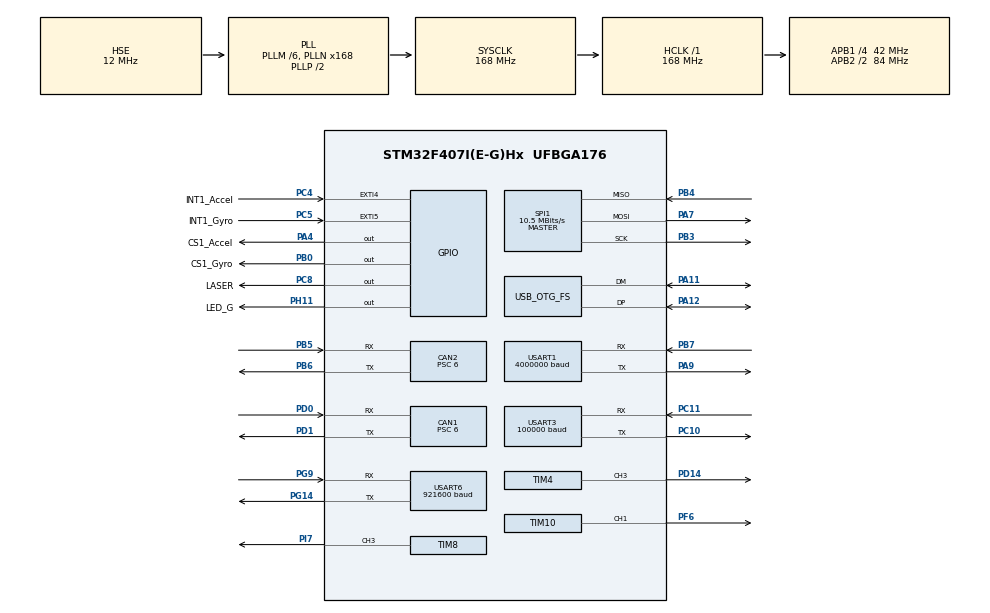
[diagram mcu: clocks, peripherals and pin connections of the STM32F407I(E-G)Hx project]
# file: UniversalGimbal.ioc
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CAN1.BS1=CAN_BS1_3TQ
CAN1.BS2=CAN_BS2_3TQ
CAN1.CalculateBaudRate=1000000
CAN1.CalculateTimeBit=1000
CAN1.CalculateTimeQuantum=142.85714285714286
CAN1.NART=ENABLE
CAN1.Prescaler=6
CAN2.BS1=CAN_BS1_3TQ
CAN2.BS2=CAN_BS2_3TQ
CAN2.CalculateBaudRate=1000000
CAN2.CalculateTimeBit=1000
CAN2.CalculateTimeQuantum=142.85714285714286
CAN2.Prescaler=6
Dma.Request0=SPI1_RX
Dma.Request1=SPI1_TX
Dma.Request2=USART6_RX
Dma.Request3=USART6_TX
Dma.Request4=USART3_RX
Dma.Request5=USART1_RX
Dma.Request6=USART1_TX
Dma.SPI1_RX.0.Direction=DMA_PERIPH_TO_MEMORY
Dma.SPI1_RX.0.FIFOMode=DMA_FIFOMODE_DISABLE
Dma.SPI1_RX.0.Instance=DMA2_Stream0
Dma.SPI1_RX.0.MemDataAlignment=DMA_MDATAALIGN_BYTE
Dma.SPI1_RX.0.MemInc=DMA_MINC_ENABLE
Dma.SPI1_RX.0.Mode=DMA_NORMAL
Dma.SPI1_RX.0.PeriphDataAlignment=DMA_PDATAALIGN_BYTE
Dma.SPI1_RX.0.PeriphInc=DMA_PINC_DISABLE
Dma.SPI1_RX.0.Priority=DMA_PRIORITY_HIGH
Dma.SPI1_TX.1.Direction=DMA_MEMORY_TO_PERIPH
Dma.SPI1_TX.1.FIFOMode=DMA_FIFOMODE_DISABLE
Dma.SPI1_TX.1.Instance=DMA2_Stream3
Dma.SPI1_TX.1.MemDataAlignment=DMA_MDATAALIGN_BYTE
Dma.SPI1_TX.1.MemInc=DMA_MINC_ENABLE
Dma.SPI1_TX.1.Mode=DMA_NORMAL
Dma.SPI1_TX.1.PeriphDataAlignment=DMA_PDATAALIGN_BYTE
Dma.SPI1_TX.1.PeriphInc=DMA_PINC_DISABLE
Dma.SPI1_TX.1.Priority=DMA_PRIORITY_HIGH
Dma.USART1_RX.5.Direction=DMA_PERIPH_TO_MEMORY
Dma.USART1_RX.5.FIFOMode=DMA_FIFOMODE_DISABLE
Dma.USART1_RX.5.Instance=DMA2_Stream2
Dma.USART1_RX.5.MemDataAlignment=DMA_MDATAALIGN_BYTE
Dma.USART1_RX.5.MemInc=DMA_MINC_ENABLE
Dma.USART1_RX.5.Mode=DMA_NORMAL
Dma.USART1_RX.5.PeriphDataAlignment=DMA_PDATAALIGN_BYTE
Dma.USART1_RX.5.PeriphInc=DMA_PINC_DISABLE
Dma.USART1_RX.5.Priority=DMA_PRIORITY_HIGH
Dma.USART1_TX.6.Direction=DMA_MEMORY_TO_PERIPH
Dma.USART1_TX.6.FIFOMode=DMA_FIFOMODE_DISABLE
Dma.USART1_TX.6.Instance=DMA2_Stream7
Dma.USART1_TX.6.MemDataAlignment=DMA_MDATAALIGN_BYTE
Dma.USART1_TX.6.MemInc=DMA_MINC_ENABLE
Dma.USART1_TX.6.Mode=DMA_NORMAL
Dma.USART1_TX.6.PeriphDataAlignment=DMA_PDATAALIGN_BYTE
Dma.USART1_TX.6.PeriphInc=DMA_PINC_DISABLE
Dma.USART1_TX.6.Priority=DMA_PRIORITY_HIGH
Dma.USART3_RX.4.Direction=DMA_PERIPH_TO_MEMORY
Dma.USART3_RX.4.FIFOMode=DMA_FIFOMODE_DISABLE
Dma.USART3_RX.4.Instance=DMA1_Stream1
Dma.USART3_RX.4.MemDataAlignment=DMA_MDATAALIGN_BYTE
Dma.USART3_RX.4.MemInc=DMA_MINC_ENABLE
Dma.USART3_RX.4.Mode=DMA_CIRCULAR
Dma.USART3_RX.4.PeriphDataAlignment=DMA_PDATAALIGN_BYTE
Dma.USART3_RX.4.PeriphInc=DMA_PINC_DISABLE
Dma.USART3_RX.4.Priority=DMA_PRIORITY_HIGH
Dma.USART6_RX.2.Direction=DMA_PERIPH_TO_MEMORY
Dma.USART6_RX.2.FIFOMode=DMA_FIFOMODE_DISABLE
Dma.USART6_RX.2.Instance=DMA2_Stream1
Dma.USART6_RX.2.MemDataAlignment=DMA_MDATAALIGN_BYTE
Dma.USART6_RX.2.MemInc=DMA_MINC_ENABLE
Dma.USART6_RX.2.Mode=DMA_NORMAL
Dma.USART6_RX.2.PeriphDataAlignment=DMA_PDATAALIGN_BYTE
Dma.USART6_RX.2.PeriphInc=DMA_PINC_DISABLE
Dma.USART6_RX.2.Priority=DMA_PRIORITY_MEDIUM
Dma.USART6_TX.3.Direction=DMA_MEMORY_TO_PERIPH
Dma.USART6_TX.3.FIFOMode=DMA_FIFOMODE_DISABLE
Dma.USART6_TX.3.Instance=DMA2_Stream6
Dma.USART6_TX.3.MemDataAlignment=DMA_MDATAALIGN_BYTE
Dma.USART6_TX.3.MemInc=DMA_MINC_ENABLE
Dma.USART6_TX.3.Mode=DMA_NORMAL
Dma.USART6_TX.3.PeriphDataAlignment=DMA_PDATAALIGN_BYTE
Dma.USART6_TX.3.PeriphInc=DMA_PINC_DISABLE
Dma.USART6_TX.3.Priority=DMA_PRIORITY_MEDIUM
FREERTOS.INCLUDE_vTaskDelayUntil=1
FREERTOS.Tasks01=Daemon,2,128,DaemonTask,As weak,NULL,Static,DaemonBuffer,DaemonControlBlock;Gimbal,0,128,GimbalTask,As weak,NULL,Static,GimbalBuffer,GimbalControlBlock;Inertial,2,1024,InertialTask,As weak,NULL,Static,InertialBuffer,InertialControlBlock;Debug,-2,128,DebugTask,As weak,NULL,Static,DebugTaskBuffer,DebugTaskControlBlock;Controller,2,128,ControllerTask,As weak,NULL,Static,ControllerBuffer,ControllerControlBlock;Vision,0,512,VisionTask,As weak,NULL,Static,VisionBuffer,VisionControlBlock
FREERTOS.configENABLE_FPU=1
FREERTOS.configTOTAL_HEAP_SIZE=16384
Mcu.Family=STM32F4
Mcu.Name=STM32F407I(E-G)Hx
Mcu.Package=UFBGA176
NVIC.CAN1_RX0_IRQn=true\:1\:0\:true\:false\:true\:false\:true\:true\:true
NVIC.CAN2_RX1_IRQn=true\:1\:0\:true\:false\:true\:false\:true\:true\:true
NVIC.DMA1_Stream1_IRQn=true\:5\:0\:true\:false\:true\:true\:false\:true\:true
NVIC.DMA2_Stream0_IRQn=true\:1\:0\:true\:false\:true\:false\:false\:true\:true
NVIC.DMA2_Stream1_IRQn=true\:5\:0\:true\:false\:true\:true\:false\:true\:true
NVIC.DMA2_Stream2_IRQn=true\:5\:0\:true\:false\:true\:true\:false\:true\:true
NVIC.DMA2_Stream3_IRQn=true\:1\:0\:true\:false\:true\:false\:false\:true\:true
NVIC.DMA2_Stream6_IRQn=true\:1\:0\:true\:false\:true\:false\:false\:true\:true
NVIC.DMA2_Stream7_IRQn=true\:5\:0\:false\:false\:true\:true\:false\:true\:true
NVIC.EXTI4_IRQn=true\:1\:0\:true\:false\:true\:false\:true\:true\:true
NVIC.EXTI9_5_IRQn=true\:1\:0\:true\:false\:true\:false\:true\:true\:true
NVIC.OTG_FS_IRQn=true\:5\:0\:false\:false\:true\:true\:false\:true\:true
NVIC.PriorityGroup=NVIC_PRIORITYGROUP_4
NVIC.SPI1_IRQn=true\:1\:0\:true\:false\:true\:false\:true\:true\:true
NVIC.TIM6_DAC_IRQn=true\:15\:0\:true\:false\:true\:false\:false\:true\:true
NVIC.TimeBase=TIM6_DAC_IRQn
NVIC.TimeBaseIP=TIM6
NVIC.USART1_IRQn=true\:5\:0\:true\:false\:true\:true\:true\:true\:true
NVIC.USART6_IRQn=true\:5\:0\:true\:false\:true\:true\:true\:true\:true
PA11.Mode=Device_Only
PA11.Signal=USB_OTG_FS_DM
PA12.Mode=Device_Only
PA12.Signal=USB_OTG_FS_DP
PA13.Mode=Serial_Wire
PA13.Signal=SYS_JTMS-SWDIO
PA14.Mode=Serial_Wire
PA14.Signal=SYS_JTCK-SWCLK
PA4.GPIO_Label=CS1_Accel
PA4.GPIO_PuPd=GPIO_PULLUP
PA4.GPIO_Speed=GPIO_SPEED_FREQ_HIGH
PA4.PinState=GPIO_PIN_SET
PA4.Signal=GPIO_Output
PA7.Mode=Full_Duplex_Master
PA7.Signal=SPI1_MOSI
PA9.Mode=Asynchronous
PA9.Signal=USART1_TX
PB0.GPIO_Label=CS1_Gyro
PB0.GPIO_PuPd=GPIO_PULLUP
PB0.GPIO_Speed=GPIO_SPEED_FREQ_HIGH
PB0.PinState=GPIO_PIN_SET
PB0.Signal=GPIO_Output
PB3.Mode=Full_Duplex_Master
PB3.Signal=SPI1_SCK
PB4.Mode=Full_Duplex_Master
PB4.Signal=SPI1_MISO
PB5.Mode=CAN_Activate
PB5.Signal=CAN2_RX
PB6.Mode=CAN_Activate
PB6.Signal=CAN2_TX
PB7.Mode=Asynchronous
PB7.Signal=USART1_RX
PC10.Mode=Asynchronous
PC10.Signal=USART3_TX
PC11.Mode=Asynchronous
PC11.Signal=USART3_RX
PC4.GPIO_Label=INT1_Accel
PC4.GPIO_ModeDefaultEXTI=GPIO_MODE_IT_FALLING
PC4.GPIO_PuPd=GPIO_PULLUP
PC4.Signal=GPXTI4
PC5.GPIO_Label=INT1_Gyro
PC5.GPIO_ModeDefaultEXTI=GPIO_MODE_IT_FALLING
PC5.GPIO_PuPd=GPIO_PULLUP
PC5.Signal=GPXTI5
PC8.GPIO_Label=LASER
PC8.PinState=GPIO_PIN_RESET
PC8.Signal=GPIO_Output
PD0.Mode=CAN_Activate
PD0.Signal=CAN1_RX
PD1.Mode=CAN_Activate
PD1.Signal=CAN1_TX
PD14.Signal=S_TIM4_CH3
PF6.Signal=S_TIM10_CH1
PG14.Mode=Asynchronous
PG14.Signal=USART6_TX
PG9.Mode=Asynchronous
PG9.Signal=USART6_RX
PH0-OSC_IN.Mode=HSE-External-Oscillator
PH0-OSC_IN.Signal=RCC_OSC_IN
PH1-OSC_OUT.Mode=HSE-External-Oscillator
PH1-OSC_OUT.Signal=RCC_OSC_OUT
PH11.GPIO_Label=LED_G
PH11.GPIO_Speed=GPIO_SPEED_FREQ_HIGH
PH11.Signal=GPIO_Output
PI7.Signal=S_TIM8_CH3
ProjectManager.HeapSize=0x400
ProjectManager.StackSize=0x800
ProjectManager.TargetToolchain=MDK-ARM V5.32
RCC.48MHZClocksFreq_Value=48000000
RCC.AHBFreq_Value=168000000
RCC.APB1CLKDivider=RCC_HCLK_DIV4
RCC.APB1Freq_Value=42000000
RCC.APB1TimFreq_Value=84000000
RCC.APB2CLKDivider=RCC_HCLK_DIV2
RCC.APB2Freq_Value=84000000
RCC.APB2TimFreq_Value=168000000
RCC.CortexFreq_Value=168000000
RCC.HCLKFreq_Value=168000000
RCC.HSE_VALUE=12000000
RCC.HSI_VALUE=16000000
RCC.LSE_VALUE=32768
RCC.PLLM=6
RCC.PLLN=168
RCC.PLLQ=7
RCC.SYSCLKFreq_VALUE=168000000
RCC.SYSCLKSource=RCC_SYSCLKSOURCE_PLLCLK
RCC.VCOOutputFreq_Value=336000000
SH.S_TIM10_CH1.0=TIM10_CH1,PWM Generation1 CH1
SH.S_TIM4_CH3.0=TIM4_CH3,PWM Generation3 CH3
SH.S_TIM8_CH3.0=TIM8_CH3,PWM Generation3 CH3
SPI1.BaudRatePrescaler=SPI_BAUDRATEPRESCALER_8
SPI1.CLKPhase=SPI_PHASE_2EDGE
SPI1.CLKPolarity=SPI_POLARITY_HIGH
SPI1.CalculateBaudRate=10.5 MBits/s
SPI1.Direction=SPI_DIRECTION_2LINES
SPI1.Mode=SPI_MODE_MASTER
SPI1.VirtualType=VM_MASTER
STMicroelectronics.X-CUBE-ALGOBUILD.1.4.0.LibraryCcDSPOoLibraryJjDSPOoLibrary=true
TIM10.Channel=TIM_CHANNEL_1
TIM10.Period=2000-1
TIM10.Prescaler=84-1
TIM4.Channel-PWM\ Generation3\ CH3=TIM_CHANNEL_3
TIM4.Period=500
TIM4.Prescaler=8400-1
TIM7.Prescaler=84-1
TIM8.Channel-PWM\ Generation3\ CH3=TIM_CHANNEL_3
TIM8.Period=2000-1
TIM8.Prescaler=1680-1
TIM8.Pulse-PWM\ Generation3\ CH3=0
USART1.BaudRate=4000000
USART1.OverSampling=UART_OVERSAMPLING_16
USART1.VirtualMode=VM_ASYNC
USART3.BaudRate=100000
USART3.Parity=PARITY_EVEN
USART3.VirtualMode=VM_ASYNC
USART6.BaudRate=921600
USART6.VirtualMode=VM_ASYNC
USB_DEVICE.CLASS_NAME_FS=CDC
USB_DEVICE.MANUFACTURER_STRING-CDC_FS=PIP x STMicroelectronics
USB_DEVICE.PRODUCT_STRING_CDC_FS=Uni-Gimbal Virtual COM
USB_DEVICE.VirtualMode-CDC_FS=Cdc
USB_DEVICE.VirtualModeFS=Cdc_FS
USB_OTG_FS.VirtualMode=Device_Only
VP_FREERTOS_VS_CMSIS_V1.Mode=CMSIS_V1
VP_STMicroelectronics.X-CUBE-ALGOBUILD_VS_DSPOoLibraryJjLibrary_1.4.0_1.4.0.Mode=DSPOoLibraryJjLibrary
VP_SYS_VS_tim6.Mode=TIM6
VP_TIM10_VS_ClockSourceINT.Mode=Enable_Timer
VP_TIM7_VS_ClockSourceINT.Mode=Enable_Timer
VP_USB_DEVICE_VS_USB_DEVICE_CDC_FS.Mode=CDC_FS
board=custom

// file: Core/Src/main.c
/* USER CODE BEGIN Header */
/**
 * @attention   采用UTF-8字符集编�?
 * @brief       主函�?
 * @authors     北工大PIP战队 樊郡�?
 * @version     v1.0
 * @date        2024-10-14
 * @details     非必要不在此编写控制逻辑的初始化 而是将其转到各模块的任务主循环前
 */
/**
  ******************************************************************************
  * @file           : main.c
  * @brief          : Main program body
  ******************************************************************************
  * @attention
  *
  * Copyright (c) 2024 STMicroelectronics.
  * All rights reserved.
  *
  * This software is licensed under terms that can be found in the LICENSE file
  * in the root directory of this software component.
  * If no LICENSE file comes with this software, it is provided AS-IS.
  *
  ******************************************************************************
  */
/* USER CODE END Header */
#include "main.h"
#include "cmsis_os.h"
#include "can.h"
#include "dma.h"
#include "spi.h"
#include "tim.h"
#include "usart.h"
#include "usb_device.h"
#include "gpio.h"

/* USER CODE BEGIN Includes */
#include "header.h"
/* USER CODE END Includes */

void SystemClock_Config(void);
void MX_FREERTOS_Init(void);

int main(void)
{

  /* MCU Configuration--------------------------------------------------------*/

  /* Reset of all peripherals, Initializes the Flash interface and the Systick. */
  HAL_Init();

  /* Configure the system clock */
  SystemClock_Config();

  /* Initialize all configured peripherals */
  MX_GPIO_Init();
  MX_DMA_Init();
  MX_CAN1_Init();
  MX_CAN2_Init();
  MX_SPI1_Init();
  MX_USART1_UART_Init();
  MX_USART6_UART_Init();
  MX_TIM4_Init();
  MX_TIM8_Init();
  MX_TIM10_Init();
  MX_USART3_UART_Init();
  MX_TIM7_Init();
  /* USER CODE BEGIN 2 */
  HAL_Delay(500);
  CAN1_UniversalInit();
  CAN2_UniversalInit();
	RC_VTM_Init();

	NUC_Init();
  /* USER CODE END 2 */

  /* Call init function for freertos objects (in cmsis_os2.c) */
  MX_FREERTOS_Init();

  /* Start scheduler */
  osKernelStart();

  /* We should never get here as control is now taken by the scheduler */

  /* Infinite loop */
  while (1)
  {

  }
}

void SystemClock_Config(void)
{
  RCC_OscInitTypeDef RCC_OscInitStruct = {0};
  RCC_ClkInitTypeDef RCC_ClkInitStruct = {0};

  /** Configure the main internal regulator output voltage
  */
  __HAL_RCC_PWR_CLK_ENABLE();
  __HAL_PWR_VOLTAGESCALING_CONFIG(PWR_REGULATOR_VOLTAGE_SCALE1);

  /** Initializes the RCC Oscillators according to the specified parameters
  * in the RCC_OscInitTypeDef structure.
  */
  RCC_OscInitStruct.OscillatorType = RCC_OSCILLATORTYPE_HSE;
  RCC_OscInitStruct.HSEState = RCC_HSE_ON;
  RCC_OscInitStruct.PLL.PLLState = RCC_PLL_ON;
  RCC_OscInitStruct.PLL.PLLSource = RCC_PLLSOURCE_HSE;
  RCC_OscInitStruct.PLL.PLLM = 6;
  RCC_OscInitStruct.PLL.PLLN = 168;
  RCC_OscInitStruct.PLL.PLLP = RCC_PLLP_DIV2;
  RCC_OscInitStruct.PLL.PLLQ = 7;
  if (HAL_RCC_OscConfig(&RCC_OscInitStruct) != HAL_OK)
  {
    Error_Handler();
  }

  /** Initializes the CPU, AHB and APB buses clocks
  */
  RCC_ClkInitStruct.ClockType = RCC_CLOCKTYPE_HCLK|RCC_CLOCKTYPE_SYSCLK
                              |RCC_CLOCKTYPE_PCLK1|RCC_CLOCKTYPE_PCLK2;
  RCC_ClkInitStruct.SYSCLKSource = RCC_SYSCLKSOURCE_PLLCLK;
  RCC_ClkInitStruct.AHBCLKDivider = RCC_SYSCLK_DIV1;
  RCC_ClkInitStruct.APB1CLKDivider = RCC_HCLK_DIV4;
  RCC_ClkInitStruct.APB2CLKDivider = RCC_HCLK_DIV2;

  if (HAL_RCC_ClockConfig(&RCC_ClkInitStruct, FLASH_LATENCY_5) != HAL_OK)
  {
    Error_Handler();
  }
}

void HAL_TIM_PeriodElapsedCallback(TIM_HandleTypeDef *htim)
{
  if (htim->Instance == TIM6)
  {
    HAL_IncTick();
  }
}

void Error_Handler(void)
{
  __disable_irq();
  while (1)
  {
  }
}

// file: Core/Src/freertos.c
/* USER CODE BEGIN Header */
/**
  ******************************************************************************
  * File Name          : freertos.c
  * Description        : Code for freertos applications
  ******************************************************************************
  * @attention
  *
  * Copyright (c) 2024 STMicroelectronics.
  * All rights reserved.
  *
  * This software is licensed under terms that can be found in the LICENSE file
  * in the root directory of this software component.
  * If no LICENSE file comes with this software, it is provided AS-IS.
  *
  ******************************************************************************
  */
/* USER CODE END Header */

#include "FreeRTOS.h"
#include "task.h"
#include "main.h"
#include "cmsis_os.h"

osThreadId DaemonHandle;
uint32_t DaemonBuffer[ 128 ];
osStaticThreadDef_t DaemonControlBlock;
osThreadId GimbalHandle;
uint32_t GimbalBuffer[ 128 ];
osStaticThreadDef_t GimbalControlBlock;
osThreadId InertialHandle;
uint32_t InertialBuffer[ 1024 ];
osStaticThreadDef_t InertialControlBlock;
osThreadId DebugHandle;
uint32_t DebugTaskBuffer[ 128 ];
osStaticThreadDef_t DebugTaskControlBlock;
osThreadId ControllerHandle;
uint32_t ControllerBuffer[ 128 ];
osStaticThreadDef_t ControllerControlBlock;
osThreadId VisionHandle;
uint32_t VisionBuffer[ 512 ];
osStaticThreadDef_t VisionControlBlock;

void DaemonTask(void const * argument);
void GimbalTask(void const * argument);
void InertialTask(void const * argument);
void DebugTask(void const * argument);
void ControllerTask(void const * argument);
void VisionTask(void const * argument);

extern void MX_USB_DEVICE_Init(void);
void MX_FREERTOS_Init(void); /* (MISRA C 2004 rule 8.1) */

/* GetIdleTaskMemory prototype (linked to static allocation support) */
void vApplicationGetIdleTaskMemory( StaticTask_t **ppxIdleTaskTCBBuffer, StackType_t **ppxIdleTaskStackBuffer, uint32_t *pulIdleTaskStackSize );

/* USER CODE BEGIN GET_IDLE_TASK_MEMORY */
static StaticTask_t xIdleTaskTCBBuffer;
static StackType_t xIdleStack[configMINIMAL_STACK_SIZE];

void vApplicationGetIdleTaskMemory( StaticTask_t **ppxIdleTaskTCBBuffer, StackType_t **ppxIdleTaskStackBuffer, uint32_t *pulIdleTaskStackSize )
{
  *ppxIdleTaskTCBBuffer = &xIdleTaskTCBBuffer;
  *ppxIdleTaskStackBuffer = &xIdleStack[0];
  *pulIdleTaskStackSize = configMINIMAL_STACK_SIZE;
  /* place for user code */
}
/* USER CODE END GET_IDLE_TASK_MEMORY */

void MX_FREERTOS_Init(void) {

  /* Create the thread(s) */
  /* definition and creation of Daemon */
  osThreadStaticDef(Daemon, DaemonTask, osPriorityHigh, 0, 128, DaemonBuffer, &DaemonControlBlock);
  DaemonHandle = osThreadCreate(osThread(Daemon), NULL);

  /* definition and creation of Gimbal */
  osThreadStaticDef(Gimbal, GimbalTask, osPriorityNormal, 0, 128, GimbalBuffer, &GimbalControlBlock);
  GimbalHandle = osThreadCreate(osThread(Gimbal), NULL);

  /* definition and creation of Inertial */
  osThreadStaticDef(Inertial, InertialTask, osPriorityHigh, 0, 1024, InertialBuffer, &InertialControlBlock);
  InertialHandle = osThreadCreate(osThread(Inertial), NULL);

  /* definition and creation of Debug */
  osThreadStaticDef(Debug, DebugTask, osPriorityLow, 0, 128, DebugTaskBuffer, &DebugTaskControlBlock);
  DebugHandle = osThreadCreate(osThread(Debug), NULL);

  /* definition and creation of Controller */
  osThreadStaticDef(Controller, ControllerTask, osPriorityHigh, 0, 128, ControllerBuffer, &ControllerControlBlock);
  ControllerHandle = osThreadCreate(osThread(Controller), NULL);

  /* definition and creation of Vision */
  osThreadStaticDef(Vision, VisionTask, osPriorityNormal, 0, 512, VisionBuffer, &VisionControlBlock);
  VisionHandle = osThreadCreate(osThread(Vision), NULL);

}

__weak void DaemonTask(void const * argument)
{
  /* init code for USB_DEVICE */
  MX_USB_DEVICE_Init();
  for(;;)
  {
    osDelay(1);
  }
}

__weak void GimbalTask(void const * argument)
{
  for(;;)
  {
    osDelay(1);
  }
}

__weak void InertialTask(void const * argument)
{
  for(;;)
  {
    osDelay(1);
  }
}

__weak void DebugTask(void const * argument)
{
  for(;;)
  {
    osDelay(1);
  }
}

__weak void ControllerTask(void const * argument)
{
  for(;;)
  {
    osDelay(1);
  }
}

__weak void VisionTask(void const * argument)
{
  for(;;)
  {
    osDelay(1);
  }
}

/* USER CODE BEGIN Application */
/**
 * @brief ���ڼ�� NUC ���ݳ�ʱ����
 */
void NucTimeoutTask(void const * argument)
{
    while (1)
    {
        NUC_TimeoutCheck();
        osDelay(10);   // 10ms ���ڵ���һ��
    }
}
/* USER CODE END Application */
